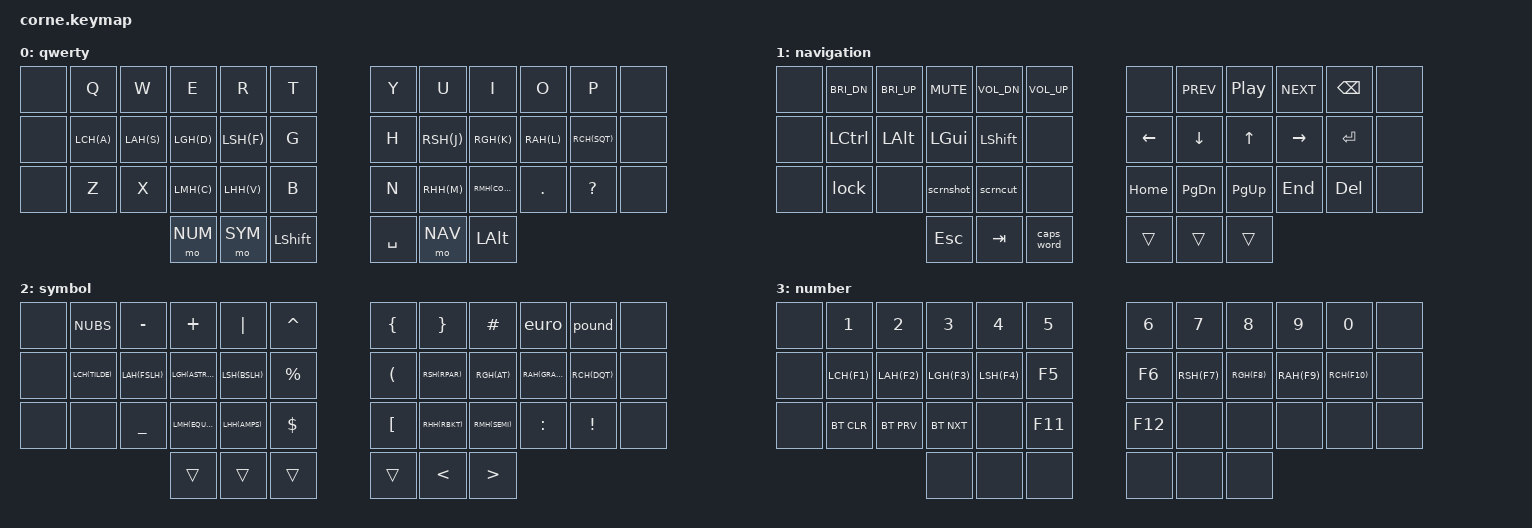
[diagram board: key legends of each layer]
#include <behaviors.dtsi>
#include <dt-bindings/zmk/keys.h>
#include <dt-bindings/zmk/bt.h>

#include "common/aliases.dtsi"
#include "common/macros.dtsi"
#include "common/behaviors.dtsi"

#define QWR 0
#define NAV 1
#define SYM 2
#define NUM 3

/ {
    keymap {
        compatible = "zmk,keymap";
        qwerty {
            bindings = <
            /*╭───────╭───────────┬───────────┬───────────┬───────────┬───────────╮                           ╭───────────┬───────────┬───────────┬───────────┬───────────╮───────╮*/
                &none   &kp Q       &kp W       &kp E       &kp R       &kp T     /*                         */ &kp Y       &kp U       &kp I       &kp O       &kp P       &none
            /*├───────├───────────┼───────────┼───────────┼───────────┼───────────┤                           ├───────────┼───────────┼───────────┼───────────┼───────────┤───────┤*/
                &none   LCH(A)      LAH(S)      LGH(D)      LSH(F)      &kp G     /*                         */ &kp H       RSH(J)      RGH(K)      RAH(L)      RCH(SQT)    &none
            /*├───────├───────────┼───────────┼───────────┼───────────┼───────────┤                           ├───────────┼───────────┼───────────┼───────────┼───────────┤───────┤*/
                &none   &kp Z       &kp X       LMH(C)      LHH(V)      &kp B     /*                         */ &kp N       RHH(M)      RMH(COMMA)  &kp DOT     &kp QMARK   &none
            /*╰───────╰───────────┴───────────┴───────────┼───────────┼───────────┼───────────╮   ╭───────────┼───────────┼───────────┼───────────┴───────────┴───────────╯───────╯*/
                                                            &mo NUM     &mo SYM     &kp LSHIFT/* */ &kp SPACE   &mo NAV     &kp LALT
            /*                                            ╰───────────┴───────────┤           │   │           ├───────────┴───────────╯                                            */
            /*                                                                    ╰───────────╯   ╰───────────╯                                                                    */
            >;
        };
        navigation {
            bindings = <
            /*╭───────╭───────────┬───────────┬───────────┬───────────┬───────────╮                           ╭───────────┬───────────┬───────────┬───────────┬───────────╮───────╮*/
                &none   &kp BRI_DN  &kp BRI_UP  &kp MUTE    &kp VOL_DN  &kp VOL_UP/*                         */ &none       &kp C_PREV  &kp C_PP    &kp C_NEXT  &kp BSPC    &none
            /*├───────├───────────┼───────────┼───────────┼───────────┼───────────┤                           ├───────────┼───────────┼───────────┼───────────┼───────────┤───────┤*/          
                &none   &kp LCTRL   &kp LALT    &kp LGUI    &kp LSHIFT  &none     /*                         */ &kp LEFT    &kp DOWN    &kp UP      &kp RIGHT   &kp RET     &none
            /*├───────├───────────┼───────────┼───────────┼───────────┼───────────┤                           ├───────────┼───────────┼───────────┼───────────┼───────────┤───────┤*/
                &none   &lock       &none       &scrnshot   &scrncut    &none     /*                         */ &kp HOME    &kp PG_DN   &kp PG_UP   &kp END     &kp DEL     &none
            /*╰───────╰───────────┴───────────┴───────────┼───────────┼───────────┼───────────╮   ╭───────────┼───────────┼───────────┼───────────┴───────────┴───────────╯───────╯*/
                                                            &kp ESC     &kp TAB     &caps_word/* */ &trans      &trans      &trans
            /*                                            ╰───────────┴───────────┤           │   │           ├───────────┴───────────╯                                            */
            /*                                                                    ╰───────────╯   ╰───────────╯                                                                    */
            >;
        };
        symbol {
            bindings = <
            /*╭───────╭───────────┬───────────┬───────────┬───────────┬───────────╮                           ╭───────────┬───────────┬───────────┬───────────┬───────────╮───────╮*/
                &none   &kp NUBS    &kp MINUS   &kp PLUS    &kp PIPE    &kp CARET /*                         */ &kp LBRC    &kp RBRC    &kp HASH    &euro       &pound      &none
            /*├───────├───────────┼───────────┼───────────┼───────────┼───────────┤                           ├───────────┼───────────┼───────────┼───────────┼───────────┤───────┤*/
                &none   LCH(TILDE)  LAH(FSLH)   LGH(ASTRK)  LSH(BSLH)   &kp PRCNT /*                         */ &kp LPAR    RSH(RPAR)   RGH(AT)     RAH(GRAVE)  RCH(DQT)    &none
            /*├───────├───────────┼───────────┼───────────┼───────────┼───────────┤                           ├───────────┼───────────┼───────────┼───────────┼───────────┤───────┤*/
                &none   &none       &kp UNDER   LMH(EQUAL)  LHH(AMPS)   &kp DLLR  /*                         */ &kp LBKT    RHH(RBKT)   RMH(SEMI)   &kp COLON   &kp EXCL    &none
            /*╰───────╰───────────┴───────────┴───────────┼───────────┼───────────┼───────────╮   ╭───────────┼───────────┼───────────┼───────────┴───────────┴───────────╯───────╯*/
                                                            &trans      &trans      &trans    /* */ &trans      &kp LT      &kp GT
            /*                                            ╰───────────┴───────────┤           │   │           ├───────────┴───────────╯                                            */
            /*                                                                    ╰───────────╯   ╰───────────╯                                                                    */
            >;
        };
        number {
            bindings = <
            /*╭───────╭───────────┬───────────┬───────────┬───────────┬───────────╮                           ╭───────────┬───────────┬───────────┬───────────┬───────────╮───────╮*/
                &none   &kp N1      &kp N2      &kp N3      &kp N4      &kp N5    /*                         */ &kp N6      &kp N7      &kp N8      &kp N9      &kp N0      &none
            /*├───────├───────────┼───────────┼───────────┼───────────┼───────────┤                           ├───────────┼───────────┼───────────┼───────────┼───────────┤───────┤*/
                &none   LCH(F1)     LAH(F2)     LGH(F3)     LSH(F4)     &kp F5    /*                         */ &kp F6      RSH(F7)     RGH(F8)     RAH(F9)     RCH(F10)    &none
            /*├───────├───────────┼───────────┼───────────┼───────────┼───────────┤                           ├───────────┼───────────┼───────────┼───────────┼───────────┤───────┤*/
                &none   &bt BT_CLR  &bt BT_PRV  &bt BT_NXT  &none       &kp F11   /*                         */ &kp F12     &none       &none       &none       &none       &none
            /*╰───────╰───────────┴───────────┴───────────┼───────────┼───────────┼───────────╮   ╭───────────┼───────────┼───────────┼───────────┴───────────┴───────────╯───────╯*/
                                                            &none       &none       &none     /* */ &none       &none       &none
            /*                                            ╰───────────┴───────────┤           │   │           ├───────────┴───────────╯                                            */
            /*                                                                    ╰───────────╯   ╰───────────╯                                                                    */
            >;
        };
    };

    /*
	  ╭────────────────────────╮ ╭────────────────────────╮
	  │  0   1   2   3   4   5 │ │  6   7   8   9  10  11 │
	  │ 12  13  14  15  16  17 │ │ 18  19  20  21  22  23 │
	  │ 24  25  26  27  28  29 │ │ 30  31  32  33  34  35 │
	  ╰───────────╮ 36  37  38 │ │ 39  40  41 ╭───────────╯
	              ╰────────────╯ ╰────────────╯            
	*/

    combos {
        compatible = "zmk,combos";

        // left side
        combo_terminal {
            timeout-ms = <50>;
            key-positions = <1 2>;
            bindings = <&term>;
        };
        combo_esc {
            timeout-ms = <50>;
            key-positions = <3 4>;
            bindings = <&kp ESC>;
        };
        combo_tab {
            timeout-ms = <50>;
            key-positions = <15 16>;
            bindings = <&kp TAB>;
        };
        combo_lshift {
            timeout-ms = <50>;
            key-positions = <27 28>;
            bindings = <&kp LSHIFT>;
        };
        
       	// right side
        combo_delete {
            timeout-ms = <50>;
            key-positions = <6 7>;
            bindings = <&kp DEL>;
        };
        combo_backspace {
            timeout-ms = <50>;
            key-positions = <7 8>;
            bindings = <&kp BSPC>;
        };
        combo_return {
            timeout-ms = <50>;
            key-positions = <19 20>;
            bindings = <&kp RET>;
        };
        combo_rshift {
            timeout-ms = <50>;
            key-positions = <31 32>;
            bindings = <&kp RSHIFT>;
        };

        // both
        combo_caps_word {
            timeout-ms = <50>;
            key-positions = <16 19>;
            bindings = <&caps_word>;
        };
    };
};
